# AT32UC3L016 device description
Architecture: AVR32_UC3; Family: AVR UC3
Registers are 32-bit, read-write, reset 0x0 unless marked. A register's access mark holds for its fields unless they carry their own. Offsets are from the block's base; [hi:lo] are bit positions; 'fields as' and 'values as' point back to an identical list.

## AST — Asynchronous Timer
Instances: AST 0xffff1c00
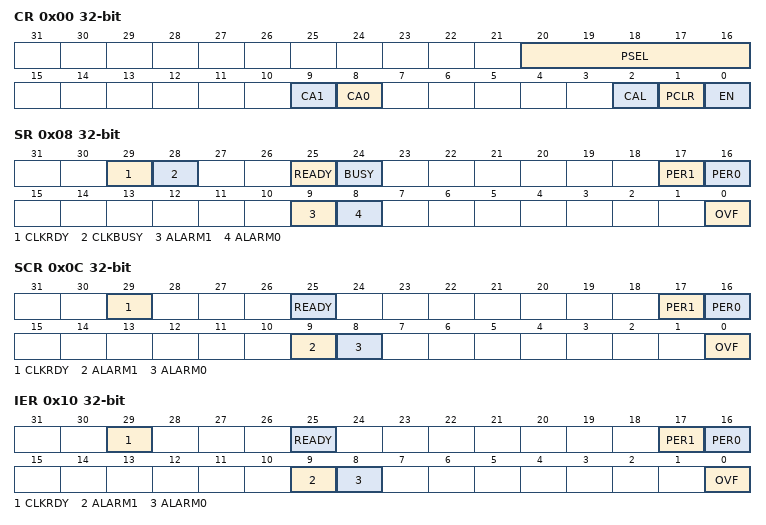
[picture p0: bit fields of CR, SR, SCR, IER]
0x00 CR — Control Register
  [20:16] PSEL — Prescale Select
  [9] CA1 — Clear on Alarm
  [8] CA0 — Clear on Alarm
  [2] CAL — Calendar mode
  [1] PCLR — Prescaler Clear (strobe)
  [0] EN — Enable
0x04 CV — Counter Value
  [31:0] VALUE — AST Value
0x08 SR ro — Status Register
  [29] CLKRDY — Clock ready
  [28] CLKBUSY — Clock busy
  [25] READY — AST ready
  [24] BUSY — AST busy
  [17] PER1 — Periodic event 1
  [16] PER0 — Periodic event 0
  [9] ALARM1 — Alarm event 1
  [8] ALARM0 — Alarm event 0
  [0] OVF — Overflow
0x0C SCR wo — Status Clear Register
  [29] CLKRDY, [25] READY, [17] PER1, [16] PER0, [9] ALARM1, [8] ALARM0, [0] OVF
0x10 IER wo — Interrupt Enable Register
  [29] CLKRDY — Clock ready
  [25] READY — AST ready
  [17] PER1 — Periodic event 1
  [16] PER0 — Periodic event 0
  [9] ALARM1 — Alarm event 1
  [8] ALARM0 — Alarm event 0
  [0] OVF — Overflow
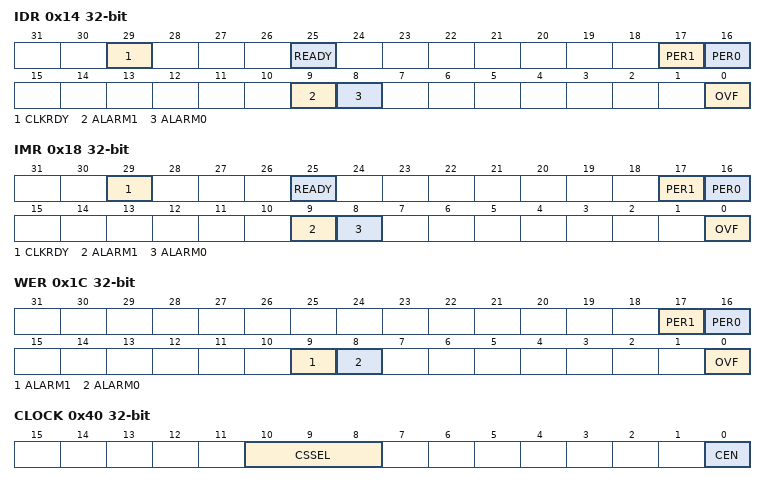
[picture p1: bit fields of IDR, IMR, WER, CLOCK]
0x14 IDR wo — Interrupt Disable Register
  fields as IER
0x18 IMR ro — Interrupt Mask Register
  fields as IER
0x1C WER — Wake Enable Register
  [17] PER1
  [16] PER0
  [9] ALARM1
  [8] ALARM0 — Alarm event 0
  [0] OVF
0x20 AR0 — Alarm Register 0
  [31:0] VALUE — Alarm Value
0x24 AR1 — Alarm Register 1
  [31:0] VALUE — Alarm Value
0x30 PIR0 — Periodic Interval Register 0
  [4:0] INSEL — Interval Select
0x34 PIR1 — Periodic Interval Register 1
  [4:0] INSEL — Interval Select
0x40 CLOCK — Clock Control Register
  [10:8] CSSEL — Clock Source Selection
    0=SLOWCLOCK; 1=32KHZCLK; 2=PBCLOCK; 3=GCLK; 4=1KHZCLK
  [0] CEN — Clock Enable
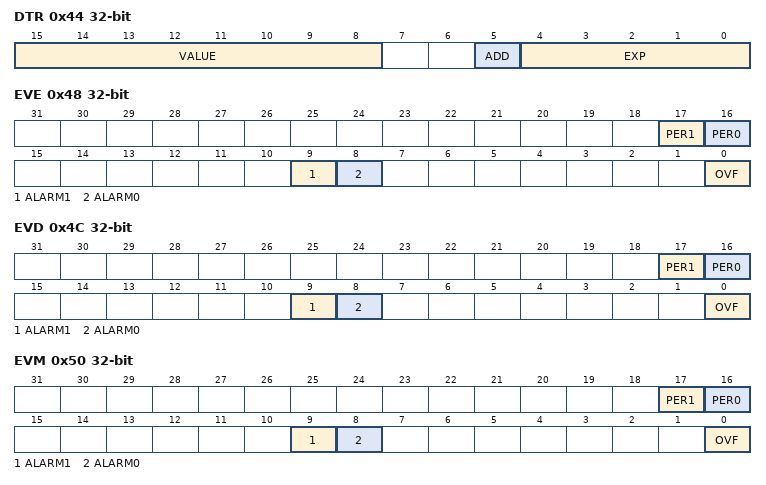
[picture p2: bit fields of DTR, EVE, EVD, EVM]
0x44 DTR — Digital Tuner Register
  [15:8] VALUE, [5] ADD, [4:0] EXP
0x48 EVE wo — Event Enable Register
  [17] PER1 — Periodic event 1
  [16] PER0 — Perioidc event 0
  [9] ALARM1 — Alarm event 1
  [8] ALARM0 — Alarm event 0
  [0] OVF — Overflow
0x4C EVD wo — Event Disable Register
  fields as EVE
0x50 EVM ro — Event Mask Register
  fields as EVE
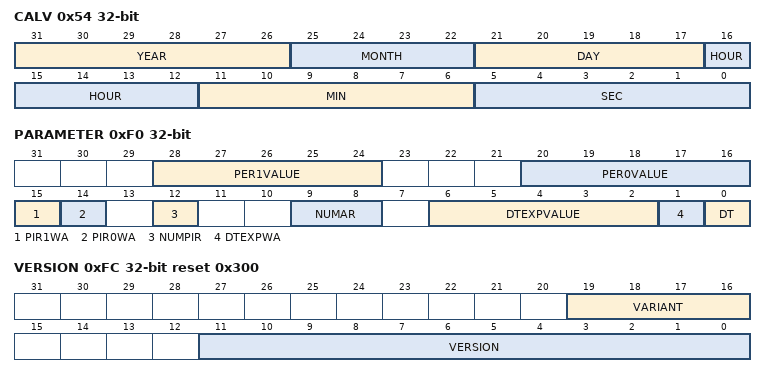
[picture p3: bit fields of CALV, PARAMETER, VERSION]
0x54 CALV — Calendar Value
  [31:26] YEAR
  [25:22] MONTH
  [21:17] DAY
  [16:12] HOUR
  [11:6] MIN — Minute
  [5:0] SEC — Second
0xF0 PARAMETER ro reset not defined
  [28:24] PER1VALUE — Periodic Interval 1 Value
  [20:16] PER0VALUE — Periodic Interval 0 Value
  [15] PIR1WA — Perioidic Interval 1 Writeable
  [14] PIR0WA — Perioidc Interval 0 Writeable
  [12] NUMPIR — Number of periodic alarms
    0=ONE; 1=TWO
  [9:8] NUMAR — Number of alarm timers
    0=ZERO; 1=ONE; 2=TWO
  [6:2] DTEXPVALUE — Digital Tuner Exponent Value
  [1] DTEXPWA — Digital Tuner Exponent Writeable
  [0] DT — Digital Tuner
    0=OFF; 1=ON
0xFC VERSION ro reset 0x300
  [19:16] VARIANT, [11:0] VERSION

## AW — aWire
Instances: AW 0xffff7000
0x00 CTRL — Control Register
  [1:0] MODE
    0=DISABLED; 1=RECEIVE; 2=TRANSMIT; 3=RECEIVESYNC
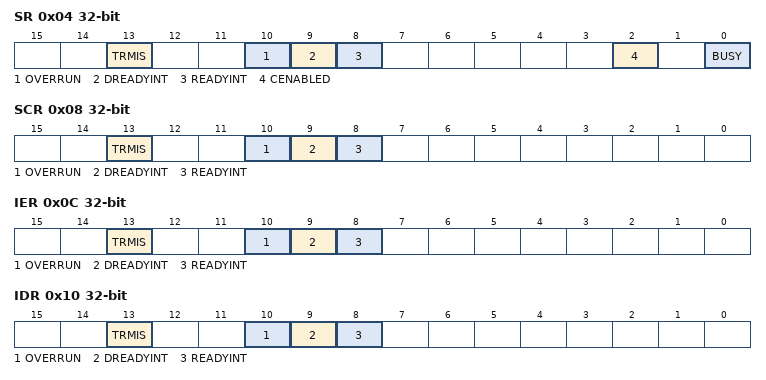
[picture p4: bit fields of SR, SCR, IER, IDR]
0x04 SR ro — Status Register
  [13] TRMIS — Transmit Mismatch
  [10] OVERRUN — Data Overrun
  [9] DREADYINT — Data Ready Interrupt
  [8] READYINT — Ready Interrupt
  [2] CENABLED — Clock Enabled
  [0] BUSY — Synchronizer Busy
0x08 SCR wo reset not defined — Status Clear Register
  [13] TRMIS — Transmit Mismatch
  [10] OVERRUN — Data Overrun
  [9] DREADYINT — Data Ready Interrupt
  [8] READYINT — Ready Interrupt
0x0C IER wo reset not defined — Interrupt Enable Register
  fields as SCR
0x10 IDR wo reset not defined — Interrupt Disable Register
  fields as SCR
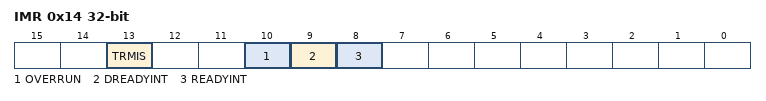
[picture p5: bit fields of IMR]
0x14 IMR ro — Interrupt Mask Register
  fields as SCR
0x18 RHR ro — Receive Holding Register
  [7:0] RXDATA
0x1C THR — Transmit Holding Register
  [7:0] TXDATA — Transmit Data
0x20 BRR — Baud Rate Register
  [15:0] BR — Baud Rate
0x24 VERSION ro reset not defined
  [11:0] VERSION — Version Number
0x28 CLKR — Clock Request Register
  [0] CLKEN — Clock Enable
    0=DISABLE; 1=ENABLE
